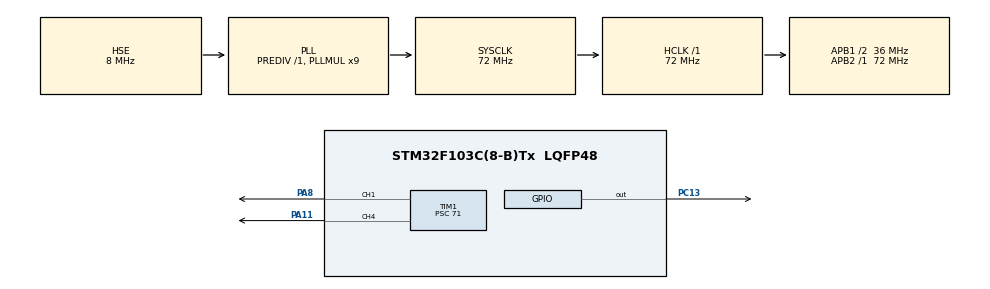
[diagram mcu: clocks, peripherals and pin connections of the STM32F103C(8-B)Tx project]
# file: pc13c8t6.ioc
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Mcu.Family=STM32F1
Mcu.Name=STM32F103C(8-B)Tx
Mcu.Package=LQFP48
NVIC.PriorityGroup=NVIC_PRIORITYGROUP_4
NVIC.TIM2_IRQn=true\:0\:0\:false\:false\:true
PA11.GPIO_Speed=GPIO_SPEED_FREQ_HIGH
PA11.Signal=S_TIM1_CH4
PA8.GPIO_Speed=GPIO_SPEED_FREQ_HIGH
PA8.Signal=S_TIM1_CH1
PC13-TAMPER-RTC.Signal=GPIO_Output
PD0-OSC_IN.Mode=HSE-External-Oscillator
PD0-OSC_IN.Signal=RCC_OSC_IN
PD1-OSC_OUT.Mode=HSE-External-Oscillator
PD1-OSC_OUT.Signal=RCC_OSC_OUT
ProjectManager.HeapSize=0x200
ProjectManager.StackSize=0x400
ProjectManager.TargetToolchain=TrueSTUDIO
RCC.AHBFreq_Value=72000000
RCC.APB1CLKDivider=RCC_HCLK_DIV2
RCC.APB1Freq_Value=36000000
RCC.APB1TimFreq_Value=72000000
RCC.APB2Freq_Value=72000000
RCC.APB2TimFreq_Value=72000000
RCC.HCLKFreq_Value=72000000
RCC.HSIState=RCC_HSI_ON
RCC.PLLMUL=RCC_PLL_MUL9
RCC.PLLSourceVirtual=RCC_PLLSOURCE_HSE
RCC.SYSCLKFreq_VALUE=72000000
RCC.SYSCLKSource=RCC_SYSCLKSOURCE_PLLCLK
RCC.USBFreq_Value=72000000
SH.S_TIM1_CH1.0=TIM1_CH1,PWM Generation1 CH1
SH.S_TIM1_CH4.0=TIM1_CH4,PWM Generation4 CH4
TIM1.Channel-PWM\ Generation4\ CH4=TIM_CHANNEL_4
TIM1.Period=999
TIM1.Prescaler=71
TIM2.Period=9999
TIM2.Prescaler=7119
VP_SYS_VS_ND.Mode=No_Debug
VP_TIM1_VS_ClockSourceINT.Mode=Internal
VP_TIM2_VS_ClockSourceINT.Mode=Internal
board=pc13c8t6

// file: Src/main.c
/**
  ******************************************************************************
  * File Name          : main.c
  * Description        : Main program body
  ******************************************************************************
  *
  * COPYRIGHT(c) 2016 STMicroelectronics
  *
  * Redistribution and use in source and binary forms, with or without modification,
  * are permitted provided that the following conditions are met:
  *   1. Redistributions of source code must retain the above copyright notice,
  *      this list of conditions and the following disclaimer.
  *   2. Redistributions in binary form must reproduce the above copyright notice,
  *      this list of conditions and the following disclaimer in the documentation
  *      and/or other materials provided with the distribution.
  *   3. Neither the name of STMicroelectronics nor the names of its contributors
  *      may be used to endorse or promote products derived from this software
  *      without specific prior written permission.
  *
  * THIS SOFTWARE IS PROVIDED BY THE COPYRIGHT HOLDERS AND CONTRIBUTORS "AS IS"
  * AND ANY EXPRESS OR IMPLIED WARRANTIES, INCLUDING, BUT NOT LIMITED TO, THE
  * IMPLIED WARRANTIES OF MERCHANTABILITY AND FITNESS FOR A PARTICULAR PURPOSE ARE
  * DISCLAIMED. IN NO EVENT SHALL THE COPYRIGHT HOLDER OR CONTRIBUTORS BE LIABLE
  * FOR ANY DIRECT, INDIRECT, INCIDENTAL, SPECIAL, EXEMPLARY, OR CONSEQUENTIAL
  * DAMAGES (INCLUDING, BUT NOT LIMITED TO, PROCUREMENT OF SUBSTITUTE GOODS OR
  * SERVICES; LOSS OF USE, DATA, OR PROFITS; OR BUSINESS INTERRUPTION) HOWEVER
  * CAUSED AND ON ANY THEORY OF LIABILITY, WHETHER IN CONTRACT, STRICT LIABILITY,
  * OR TORT (INCLUDING NEGLIGENCE OR OTHERWISE) ARISING IN ANY WAY OUT OF THE USE
  * OF THIS SOFTWARE, EVEN IF ADVISED OF THE POSSIBILITY OF SUCH DAMAGE.
  *
  ******************************************************************************
  */
#include "main.h"
#include "stm32f1xx_hal.h"

TIM_HandleTypeDef htim1;
TIM_HandleTypeDef htim2;

/* USER CODE BEGIN PV */
/* Private variables ---------------------------------------------------------*/

/* USER CODE END PV */

void SystemClock_Config(void);
void Error_Handler(void);
static void MX_GPIO_Init(void);
static void MX_TIM2_Init(void);
static void MX_TIM1_Init(void);
void HAL_TIM_MspPostInit(TIM_HandleTypeDef *htim);

/* USER CODE BEGIN PFP */
/* Private function prototypes -----------------------------------------------*/
void HAL_TIM_PeriodElapsedCallback(TIM_HandleTypeDef *htim);

/* USER CODE END PFP */

/* USER CODE BEGIN 0 */
void HAL_TIM_PeriodElapsedCallback(TIM_HandleTypeDef *htim)
{
	if(htim->Instance==TIM2) {
		HAL_GPIO_TogglePin(GPIOC, GPIO_PIN_13);

	}
}
/* USER CODE END 0 */

int main(void)
{

  /* MCU Configuration----------------------------------------------------------*/

  /* Reset of all peripherals, Initializes the Flash interface and the Systick. */
  HAL_Init();

  /* Configure the system clock */
  SystemClock_Config();

  /* Initialize all configured peripherals */
  MX_GPIO_Init();
  MX_TIM2_Init();
  MX_TIM1_Init();

  /* USER CODE BEGIN 2 */
  while(HAL_TIM_Base_Start_IT(&htim2)!=HAL_OK);

  while(HAL_TIM_PWM_Start(&htim1,TIM_CHANNEL_1 )!=HAL_OK);
  while(HAL_TIM_PWM_Start(&htim1,TIM_CHANNEL_4 )!=HAL_OK);
  /* USER CODE END 2 */

  /* Infinite loop */
  /* USER CODE BEGIN WHILE */
  int x = 0;
  while (1)
  {
  /* USER CODE END WHILE */

  /* USER CODE BEGIN 3 */
	  if(x==1000) x = 0;
	  TIM1->CCR1 = x;
	  x+=1;
	  HAL_Delay(3);
  }
  /* USER CODE END 3 */

}

/** System Clock Configuration
*/
void SystemClock_Config(void)
{

  RCC_OscInitTypeDef RCC_OscInitStruct;
  RCC_ClkInitTypeDef RCC_ClkInitStruct;

    /**Initializes the CPU, AHB and APB busses clocks
    */
  RCC_OscInitStruct.OscillatorType = RCC_OSCILLATORTYPE_HSE;
  RCC_OscInitStruct.HSEState = RCC_HSE_ON;
  RCC_OscInitStruct.HSEPredivValue = RCC_HSE_PREDIV_DIV1;
  RCC_OscInitStruct.HSIState = RCC_HSI_ON;
  RCC_OscInitStruct.PLL.PLLState = RCC_PLL_ON;
  RCC_OscInitStruct.PLL.PLLSource = RCC_PLLSOURCE_HSE;
  RCC_OscInitStruct.PLL.PLLMUL = RCC_PLL_MUL9;
  if (HAL_RCC_OscConfig(&RCC_OscInitStruct) != HAL_OK)
  {
    Error_Handler();
  }

    /**Initializes the CPU, AHB and APB busses clocks
    */
  RCC_ClkInitStruct.ClockType = RCC_CLOCKTYPE_HCLK|RCC_CLOCKTYPE_SYSCLK
                              |RCC_CLOCKTYPE_PCLK1|RCC_CLOCKTYPE_PCLK2;
  RCC_ClkInitStruct.SYSCLKSource = RCC_SYSCLKSOURCE_PLLCLK;
  RCC_ClkInitStruct.AHBCLKDivider = RCC_SYSCLK_DIV1;
  RCC_ClkInitStruct.APB1CLKDivider = RCC_HCLK_DIV2;
  RCC_ClkInitStruct.APB2CLKDivider = RCC_HCLK_DIV1;

  if (HAL_RCC_ClockConfig(&RCC_ClkInitStruct, FLASH_LATENCY_2) != HAL_OK)
  {
    Error_Handler();
  }

    /**Configure the Systick interrupt time
    */
  HAL_SYSTICK_Config(HAL_RCC_GetHCLKFreq()/1000);

    /**Configure the Systick
    */
  HAL_SYSTICK_CLKSourceConfig(SYSTICK_CLKSOURCE_HCLK);

  /* SysTick_IRQn interrupt configuration */
  HAL_NVIC_SetPriority(SysTick_IRQn, 0, 0);
}

/* TIM1 init function */
static void MX_TIM1_Init(void)
{

  TIM_ClockConfigTypeDef sClockSourceConfig;
  TIM_MasterConfigTypeDef sMasterConfig;
  TIM_OC_InitTypeDef sConfigOC;
  TIM_BreakDeadTimeConfigTypeDef sBreakDeadTimeConfig;

  htim1.Instance = TIM1;
  htim1.Init.Prescaler = 71;
  htim1.Init.CounterMode = TIM_COUNTERMODE_UP;
  htim1.Init.Period = 999;
  htim1.Init.ClockDivision = TIM_CLOCKDIVISION_DIV1;
  htim1.Init.RepetitionCounter = 0;
  if (HAL_TIM_Base_Init(&htim1) != HAL_OK)
  {
    Error_Handler();
  }

  sClockSourceConfig.ClockSource = TIM_CLOCKSOURCE_INTERNAL;
  if (HAL_TIM_ConfigClockSource(&htim1, &sClockSourceConfig) != HAL_OK)
  {
    Error_Handler();
  }

  if (HAL_TIM_PWM_Init(&htim1) != HAL_OK)
  {
    Error_Handler();
  }

  sMasterConfig.MasterOutputTrigger = TIM_TRGO_RESET;
  sMasterConfig.MasterSlaveMode = TIM_MASTERSLAVEMODE_DISABLE;
  if (HAL_TIMEx_MasterConfigSynchronization(&htim1, &sMasterConfig) != HAL_OK)
  {
    Error_Handler();
  }

  sConfigOC.OCMode = TIM_OCMODE_PWM1;
  sConfigOC.Pulse = 0;
  sConfigOC.OCPolarity = TIM_OCPOLARITY_HIGH;
  sConfigOC.OCNPolarity = TIM_OCNPOLARITY_HIGH;
  sConfigOC.OCFastMode = TIM_OCFAST_DISABLE;
  sConfigOC.OCIdleState = TIM_OCIDLESTATE_RESET;
  sConfigOC.OCNIdleState = TIM_OCNIDLESTATE_RESET;
  if (HAL_TIM_PWM_ConfigChannel(&htim1, &sConfigOC, TIM_CHANNEL_1) != HAL_OK)
  {
    Error_Handler();
  }

  if (HAL_TIM_PWM_ConfigChannel(&htim1, &sConfigOC, TIM_CHANNEL_4) != HAL_OK)
  {
    Error_Handler();
  }

  sBreakDeadTimeConfig.OffStateRunMode = TIM_OSSR_DISABLE;
  sBreakDeadTimeConfig.OffStateIDLEMode = TIM_OSSI_DISABLE;
  sBreakDeadTimeConfig.LockLevel = TIM_LOCKLEVEL_OFF;
  sBreakDeadTimeConfig.DeadTime = 0;
  sBreakDeadTimeConfig.BreakState = TIM_BREAK_DISABLE;
  sBreakDeadTimeConfig.BreakPolarity = TIM_BREAKPOLARITY_HIGH;
  sBreakDeadTimeConfig.AutomaticOutput = TIM_AUTOMATICOUTPUT_DISABLE;
  if (HAL_TIMEx_ConfigBreakDeadTime(&htim1, &sBreakDeadTimeConfig) != HAL_OK)
  {
    Error_Handler();
  }

  HAL_TIM_MspPostInit(&htim1);

}

/* TIM2 init function */
static void MX_TIM2_Init(void)
{

  TIM_ClockConfigTypeDef sClockSourceConfig;
  TIM_MasterConfigTypeDef sMasterConfig;

  htim2.Instance = TIM2;
  htim2.Init.Prescaler = 7119;
  htim2.Init.CounterMode = TIM_COUNTERMODE_UP;
  htim2.Init.Period = 9999;
  htim2.Init.ClockDivision = TIM_CLOCKDIVISION_DIV1;
  if (HAL_TIM_Base_Init(&htim2) != HAL_OK)
  {
    Error_Handler();
  }

  sClockSourceConfig.ClockSource = TIM_CLOCKSOURCE_INTERNAL;
  if (HAL_TIM_ConfigClockSource(&htim2, &sClockSourceConfig) != HAL_OK)
  {
    Error_Handler();
  }

  sMasterConfig.MasterOutputTrigger = TIM_TRGO_RESET;
  sMasterConfig.MasterSlaveMode = TIM_MASTERSLAVEMODE_DISABLE;
  if (HAL_TIMEx_MasterConfigSynchronization(&htim2, &sMasterConfig) != HAL_OK)
  {
    Error_Handler();
  }

}

/** Configure pins as
        * Analog
        * Input
        * Output
        * EVENT_OUT
        * EXTI
*/
static void MX_GPIO_Init(void)
{

  GPIO_InitTypeDef GPIO_InitStruct;

  /* GPIO Ports Clock Enable */
  __HAL_RCC_GPIOC_CLK_ENABLE();
  __HAL_RCC_GPIOD_CLK_ENABLE();
  __HAL_RCC_GPIOA_CLK_ENABLE();

  /*Configure GPIO pin Output Level */
  HAL_GPIO_WritePin(GPIOC, GPIO_PIN_13, GPIO_PIN_RESET);

  /*Configure GPIO pin : PC13 */
  GPIO_InitStruct.Pin = GPIO_PIN_13;
  GPIO_InitStruct.Mode = GPIO_MODE_OUTPUT_PP;
  GPIO_InitStruct.Speed = GPIO_SPEED_FREQ_LOW;
  HAL_GPIO_Init(GPIOC, &GPIO_InitStruct);

}

void Error_Handler(void)
{
  while(1)
  {
  }
}

/************************ (C) COPYRIGHT STMicroelectronics *****END OF FILE****/
